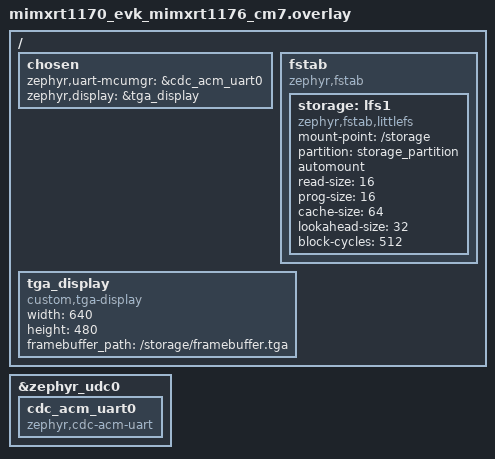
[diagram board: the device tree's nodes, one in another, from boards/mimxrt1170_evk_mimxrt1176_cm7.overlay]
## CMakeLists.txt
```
cmake_minimum_required(VERSION 3.13.1)

# Set default board
set(BOARD "mimxrt1170_evk@B/mimxrt1176/cm7" CACHE STRING "Selected Board")

find_package(Zephyr-sdk 0.17.2 EXACT REQUIRED)
find_package(Zephyr 4.2.0 EXACT REQUIRED HINTS $ENV{ZEPHYR_BASE})
project(app LANGUAGES C CXX)

target_compile_options(app PRIVATE
    -Wall -Wextra
    # Checks that are incompatible with Zephyr
    -Wno-variadic-macros
    -Wno-type-limits
)

add_subdirectory(src)
```

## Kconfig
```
# This file is the application Kconfig entry point. All application Kconfig
# options can be defined here or included via other application Kconfig files.
# You can browse these options using the west targets menuconfig (terminal) or
# guiconfig (GUI).

menu "Zephyr"
source "Kconfig.zephyr"
endmenu

module = APP
module-str = App
source "subsys/logging/Kconfig.template.log_config"
```

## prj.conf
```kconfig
# Copyright (c) 2021 Nordic Semiconductor ASA
# SPDX-License-Identifier: Apache-2.0
#
# This file contains selected Kconfig options for the application.

# Disable boot banner, as it gets printed too late
# CONFIG_BOOT_BANNER=n

# Stack size; increase this if you get:
#  <err> os: >>> ZEPHYR FATAL ERROR 2: Stack overflow on CPU 0
#  <err> os: Current thread: 0x... (main)
CONFIG_MAIN_STACK_SIZE=8192
CONFIG_HEAP_MEM_POOL_SIZE=8192

# Subsystems
CONFIG_FLASH=y
CONFIG_FLASH_MAP=y
CONFIG_STREAM_FLASH=y
CONFIG_FILE_SYSTEM=y
CONFIG_FILE_SYSTEM_LITTLEFS=y
CONFIG_ZCBOR=y

# MCUmgr
CONFIG_MCUMGR=y
CONFIG_MCUMGR_TRANSPORT_UART=y
CONFIG_SERIAL=y
CONFIG_CRC=y
CONFIG_BASE64=y
CONFIG_MBEDTLS=y
CONFIG_MBEDTLS_SHA256=y
CONFIG_MCUMGR_GRP_OS=y
CONFIG_MCUMGR_GRP_OS_INFO=y
CONFIG_MCUMGR_GRP_OS_INFO_BUILD_DATE_TIME=y
CONFIG_MCUMGR_GRP_OS_MCUMGR_PARAMS=y
CONFIG_MCUMGR_GRP_FS=y
CONFIG_MCUMGR_GRP_FS_CHECKSUM_HASH=y
CONFIG_MCUMGR_GRP_FS_CHECKSUM_HASH_SUPPORTED_CMD=y
CONFIG_MCUMGR_GRP_FS_FILE_STATUS=y
CONFIG_MCUMGR_GRP_FS_HASH_SHA256=y
CONFIG_MCUMGR_GRP_FS_MAX_FILE_SIZE_4GB=y

# USB
CONFIG_USB_DEVICE_STACK_NEXT=y
CONFIG_USBD_CDC_ACM_CLASS=y
CONFIG_USBD_LOG_LEVEL_WRN=y
CONFIG_UDC_DRIVER_LOG_LEVEL_WRN=y
# CDC ACM logs need to be disabled when logs go through CDC ACM
CONFIG_USBD_CDC_ACM_LOG_LEVEL_OFF=y
CONFIG_CDC_ACM_SERIAL_INITIALIZE_AT_BOOT=y

CONFIG_UART_LINE_CTRL=y

# Logging
CONFIG_LOG=y
CONFIG_LOG_BUFFER_SIZE=4096

# LVGL
CONFIG_LVGL=y

# LVGL Internal Settings
CONFIG_LV_USE_LOG=y
CONFIG_LV_COLOR_DEPTH_32=y
CONFIG_LV_USE_PXP=y
# collides with lvgl pxp
CONFIG_MCUX_PXP=n

# LVGL Zephyr Settings
CONFIG_LV_Z_MEM_POOL_SYS_HEAP=y
CONFIG_LV_Z_MEM_POOL_SIZE=65536
CONFIG_LV_Z_VDB_SIZE=10
CONFIG_LV_Z_DOUBLE_VDB=y
CONFIG_LV_Z_BUFFER_ALLOC_STATIC=y
CONFIG_LV_Z_FLUSH_THREAD=y
CONFIG_LV_Z_USE_FILESYSTEM=n

# Set flush thread as very lowest priority because it will
# lag the system horribly
CONFIG_LV_Z_FLUSH_THREAD_PRIORITY=14
CONFIG_LOG_PROCESS_THREAD_CUSTOM_PRIORITY=y
CONFIG_LOG_PROCESS_THREAD_PRIORITY=13
CONFIG_SHELL_THREAD_PRIORITY_OVERRIDE=y
CONFIG_SHELL_THREAD_PRIORITY=13

# Shell
CONFIG_SHELL=y
CONFIG_SHELL_LOG_BACKEND=y
CONFIG_FILE_SYSTEM_SHELL=y
CONFIG_LV_Z_SHELL=y

# Display
CONFIG_DISPLAY=y
CONFIG_DISPLAY_LOG_LEVEL_DBG=y
CONFIG_TGA_DISPLAY=y
```

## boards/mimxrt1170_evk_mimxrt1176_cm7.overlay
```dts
/ {
    chosen {
        zephyr,uart-mcumgr = &cdc_acm_uart0;
        zephyr,display = &tga_display;
    };

    fstab {
        compatible = "zephyr,fstab";
        storage: lfs1 {
            compatible = "zephyr,fstab,littlefs";
            mount-point = "/storage";
            partition = <&storage_partition>;
            automount;
            read-size = <16>;
            prog-size = <16>;
            cache-size = <64>;
            lookahead-size = <32>;
            block-cycles = <512>;
        };
    };

    tga_display: tga_display {
        compatible = "custom,tga-display";
        width = <640>;
        height = <480>;
        framebuffer_path = "/storage/framebuffer.tga";
		status = "okay";
    };
};

&zephyr_udc0 {
    cdc_acm_uart0: cdc_acm_uart0 {
        compatible = "zephyr,cdc-acm-uart";
    };
};
```

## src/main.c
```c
#include <zephyr/drivers/display.h>
#include <zephyr/logging/log.h>

#include <app_version.h>
#include <math.h>
#include <stdint.h>
#include <stdio.h>

#include "gui.h"

LOG_MODULE_REGISTER(app, CONFIG_APP_LOG_LEVEL);

int main(void)
{
    LOG_INF("My Test Application %s (git: %s)", APP_VERSION_STRING, STRINGIFY(APP_BUILD_VERSION));

    gui_run();

    return 0;
}
```

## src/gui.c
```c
#include "gui.h"

#include <zephyr/drivers/display.h>
#include <zephyr/kernel.h>

#include <lvgl.h>

void render_test_image(lv_obj_t *parent)
{
    static lv_style_t st;
    lv_style_init(&st);
    lv_style_set_pad_all(&st, 0);
    lv_style_set_radius(&st, 0);
    lv_style_set_bg_color(&st, lv_color_black());
    lv_style_set_border_color(&st, lv_color_white());
    lv_style_set_border_width(&st, 1);

    lv_obj_t *border = lv_obj_create(parent);
    lv_obj_set_size(border, LV_PCT(100), LV_PCT(100));
    lv_obj_add_style(border, &st, 0);
    lv_obj_align(border, LV_ALIGN_CENTER, 0, 0);

    lv_obj_t *half_border = lv_obj_create(parent);
    lv_obj_set_size(half_border, LV_PCT(50), LV_PCT(50));
    lv_obj_add_style(half_border, &st, 0);
    lv_obj_align(half_border, LV_ALIGN_CENTER, 0, 0);

    lv_coord_t w         = lv_obj_get_width(parent);
    lv_coord_t h         = lv_obj_get_height(parent);
    lv_coord_t grid_size = h / 6;

    for (lv_coord_t y = grid_size; y < h; y += grid_size) {
        lv_obj_t *line = lv_obj_create(parent);
        lv_obj_align(line, LV_ALIGN_TOP_LEFT, 0, y - 1);
        lv_obj_set_size(line, LV_PCT(100), 2);
        lv_obj_add_style(line, &st, 0);
    }

    for (lv_coord_t x = grid_size; x < w; x += grid_size) {
        lv_obj_t *line = lv_obj_create(parent);
        lv_obj_align(line, LV_ALIGN_TOP_LEFT, x - 1, 0);
        lv_obj_set_size(line, 2, LV_PCT(100));
        lv_obj_add_style(line, &st, 0);
    }

    int num_circles = Z_MIN(w, h) / (2 * grid_size);
    for (int i = 1; i <= num_circles; i++) {
        lv_obj_t *circle = lv_obj_create(parent);
        lv_obj_set_style_pad_all(circle, 0, 0);
        lv_obj_set_style_radius(circle, LV_RADIUS_CIRCLE, 0);
        lv_obj_set_style_bg_opa(circle, 0, 0);
        lv_obj_set_style_border_color(circle, lv_color_white(), 0);
        lv_obj_set_style_border_width(circle, 1, 0);
        lv_obj_align(circle, LV_ALIGN_CENTER, 0, 0);
        lv_obj_set_size(circle, 2 * i * grid_size, 2 * i * grid_size);
    }
}

void gui_run(void)
{
    const struct device *display_dev = DEVICE_DT_GET(DT_CHOSEN(zephyr_display));

    /* Set background color to black transparent */
    lv_obj_set_style_bg_opa(lv_screen_active(), LV_OPA_TRANSP, LV_PART_MAIN);
    lv_obj_set_style_bg_opa(lv_layer_bottom(), LV_OPA_TRANSP, LV_PART_MAIN);

    render_test_image(lv_screen_active());

    lv_timer_handler();
    display_blanking_off(display_dev);

    while (1) {
        uint32_t sleep_ms = lv_timer_handler();

        k_msleep(MIN(sleep_ms, INT32_MAX));
    }
}
```
